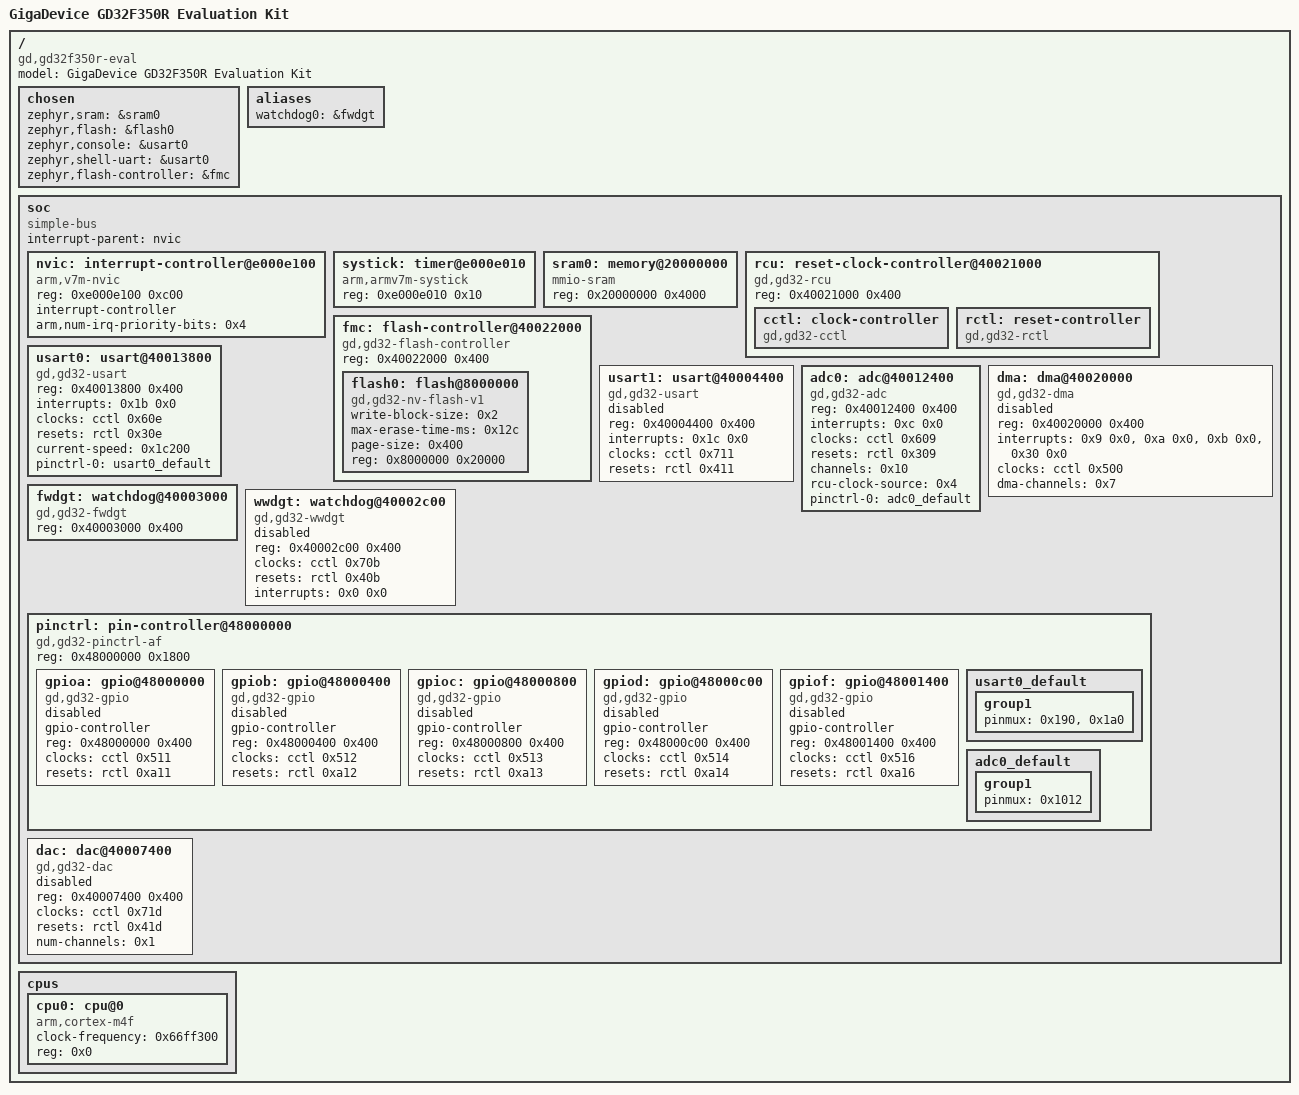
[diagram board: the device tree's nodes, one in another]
/dts-v1/;

/* node '/' defined in zephyr/dts/common/skeleton.dtsi:9 */
/ {
	#address-cells = < 0x1 >;                      /* in zephyr/dts/common/skeleton.dtsi:10 */
	#size-cells = < 0x1 >;                         /* in zephyr/dts/common/skeleton.dtsi:11 */
	model = "GigaDevice GD32F350R Evaluation Kit"; /* in zephyr/boards/gd/gd32f350r_eval/gd32f350r_eval.dts:12 */
	compatible = "gd,gd32f350r-eval";              /* in zephyr/boards/gd/gd32f350r_eval/gd32f350r_eval.dts:13 */

	/* node '/chosen' defined in zephyr/dts/common/skeleton.dtsi:13 */
	chosen {
		zephyr,sram = &sram0;           /* in zephyr/boards/gd/gd32f350r_eval/gd32f350r_eval.dts:16 */
		zephyr,flash = &flash0;         /* in zephyr/boards/gd/gd32f350r_eval/gd32f350r_eval.dts:17 */
		zephyr,console = &usart0;       /* in zephyr/boards/gd/gd32f350r_eval/gd32f350r_eval.dts:18 */
		zephyr,shell-uart = &usart0;    /* in zephyr/boards/gd/gd32f350r_eval/gd32f350r_eval.dts:19 */
		zephyr,flash-controller = &fmc; /* in zephyr/boards/gd/gd32f350r_eval/gd32f350r_eval.dts:20 */
	};

	/* node '/aliases' defined in zephyr/dts/common/skeleton.dtsi:15 */
	aliases {
		watchdog0 = &fwdgt; /* in zephyr/boards/gd/gd32f350r_eval/gd32f350r_eval.dts:24 */
	};

	/* node '/soc' defined in zephyr/dts/arm/armv7-m.dtsi:6 */
	soc {
		#address-cells = < 0x1 >;     /* in zephyr/dts/arm/armv7-m.dtsi:7 */
		#size-cells = < 0x1 >;        /* in zephyr/dts/arm/armv7-m.dtsi:8 */
		compatible = "simple-bus";    /* in zephyr/dts/arm/armv7-m.dtsi:9 */
		interrupt-parent = < &nvic >; /* in zephyr/dts/arm/armv7-m.dtsi:10 */
		ranges;                       /* in zephyr/dts/arm/armv7-m.dtsi:11 */

		/* node '/soc/interrupt-controller@e000e100' defined in zephyr/dts/arm/armv7-m.dtsi:13 */
		nvic: interrupt-controller@e000e100 {
			#address-cells = < 0x1 >;            /* in zephyr/dts/arm/armv7-m.dtsi:14 */
			compatible = "arm,v7m-nvic";         /* in zephyr/dts/arm/armv7-m.dtsi:15 */
			reg = < 0xe000e100 0xc00 >;          /* in zephyr/dts/arm/armv7-m.dtsi:16 */
			interrupt-controller;                /* in zephyr/dts/arm/armv7-m.dtsi:17 */
			#interrupt-cells = < 0x2 >;          /* in zephyr/dts/arm/armv7-m.dtsi:18 */
			arm,num-irq-priority-bits = < 0x4 >; /* in zephyr/dts/arm/gd/gd32f3x0/gd32f3x0.dtsi:181 */
			phandle = < 0x1 >;                   /* in zephyr/dts/arm/armv7-m.dtsi:10 */
		};

		/* node '/soc/timer@e000e010' defined in zephyr/dts/arm/armv7-m.dtsi:21 */
		systick: timer@e000e010 {
			compatible = "arm,armv7m-systick"; /* in zephyr/dts/arm/armv7-m.dtsi:22 */
			reg = < 0xe000e010 0x10 >;         /* in zephyr/dts/arm/armv7-m.dtsi:23 */
		};

		/* node '/soc/memory@20000000' defined in zephyr/dts/arm/gd/gd32f3x0/gd32f3x0.dtsi:28 */
		sram0: memory@20000000 {
			compatible = "mmio-sram";    /* in zephyr/dts/arm/gd/gd32f3x0/gd32f3x0.dtsi:29 */
			reg = < 0x20000000 0x4000 >; /* in zephyr/dts/arm/gd/gd32f3x0/gd32f350rb.dtsi:15 */
		};

		/* node '/soc/reset-clock-controller@40021000' defined in zephyr/dts/arm/gd/gd32f3x0/gd32f3x0.dtsi:32 */
		rcu: reset-clock-controller@40021000 {
			compatible = "gd,gd32-rcu"; /* in zephyr/dts/arm/gd/gd32f3x0/gd32f3x0.dtsi:33 */
			reg = < 0x40021000 0x400 >; /* in zephyr/dts/arm/gd/gd32f3x0/gd32f3x0.dtsi:34 */
			status = "okay";            /* in zephyr/dts/arm/gd/gd32f3x0/gd32f3x0.dtsi:35 */

			/* node '/soc/reset-clock-controller@40021000/clock-controller' defined in zephyr/dts/arm/gd/gd32f3x0/gd32f3x0.dtsi:37 */
			cctl: clock-controller {
				compatible = "gd,gd32-cctl"; /* in zephyr/dts/arm/gd/gd32f3x0/gd32f3x0.dtsi:38 */
				#clock-cells = < 0x1 >;      /* in zephyr/dts/arm/gd/gd32f3x0/gd32f3x0.dtsi:39 */
				status = "okay";             /* in zephyr/dts/arm/gd/gd32f3x0/gd32f3x0.dtsi:40 */
				phandle = < 0x2 >;           /* in zephyr/dts/arm/gd/gd32f3x0/gd32f3x0.dtsi:69 */
			};

			/* node '/soc/reset-clock-controller@40021000/reset-controller' defined in zephyr/dts/arm/gd/gd32f3x0/gd32f3x0.dtsi:43 */
			rctl: reset-controller {
				compatible = "gd,gd32-rctl"; /* in zephyr/dts/arm/gd/gd32f3x0/gd32f3x0.dtsi:44 */
				#reset-cells = < 0x1 >;      /* in zephyr/dts/arm/gd/gd32f3x0/gd32f3x0.dtsi:45 */
				status = "okay";             /* in zephyr/dts/arm/gd/gd32f3x0/gd32f3x0.dtsi:46 */
				phandle = < 0x3 >;           /* in zephyr/dts/arm/gd/gd32f3x0/gd32f3x0.dtsi:70 */
			};
		};

		/* node '/soc/flash-controller@40022000' defined in zephyr/dts/arm/gd/gd32f3x0/gd32f3x0.dtsi:50 */
		fmc: flash-controller@40022000 {
			compatible = "gd,gd32-flash-controller"; /* in zephyr/dts/arm/gd/gd32f3x0/gd32f3x0.dtsi:51 */
			reg = < 0x40022000 0x400 >;              /* in zephyr/dts/arm/gd/gd32f3x0/gd32f3x0.dtsi:52 */
			#address-cells = < 0x1 >;                /* in zephyr/dts/arm/gd/gd32f3x0/gd32f3x0.dtsi:54 */
			#size-cells = < 0x1 >;                   /* in zephyr/dts/arm/gd/gd32f3x0/gd32f3x0.dtsi:55 */

			/* node '/soc/flash-controller@40022000/flash@8000000' defined in zephyr/dts/arm/gd/gd32f3x0/gd32f3x0.dtsi:57 */
			flash0: flash@8000000 {
				compatible = "gd,gd32-nv-flash-v1",
				             "soc-nv-flash";        /* in zephyr/dts/arm/gd/gd32f3x0/gd32f3x0.dtsi:58 */
				write-block-size = < 0x2 >;         /* in zephyr/dts/arm/gd/gd32f3x0/gd32f3x0.dtsi:59 */
				max-erase-time-ms = < 0x12c >;      /* in zephyr/dts/arm/gd/gd32f3x0/gd32f3x0.dtsi:60 */
				page-size = < 0x400 >;              /* in zephyr/dts/arm/gd/gd32f3x0/gd32f3x0.dtsi:61 */
				reg = < 0x8000000 0x20000 >;        /* in zephyr/dts/arm/gd/gd32f3x0/gd32f350rb.dtsi:11 */
			};
		};

		/* node '/soc/usart@40013800' defined in zephyr/dts/arm/gd/gd32f3x0/gd32f3x0.dtsi:65 */
		usart0: usart@40013800 {
			compatible = "gd,gd32-usart";    /* in zephyr/dts/arm/gd/gd32f3x0/gd32f3x0.dtsi:66 */
			reg = < 0x40013800 0x400 >;      /* in zephyr/dts/arm/gd/gd32f3x0/gd32f3x0.dtsi:67 */
			interrupts = < 0x1b 0x0 >;       /* in zephyr/dts/arm/gd/gd32f3x0/gd32f3x0.dtsi:68 */
			clocks = < &cctl 0x60e >;        /* in zephyr/dts/arm/gd/gd32f3x0/gd32f3x0.dtsi:69 */
			resets = < &rctl 0x30e >;        /* in zephyr/dts/arm/gd/gd32f3x0/gd32f3x0.dtsi:70 */
			status = "okay";                 /* in zephyr/boards/gd/gd32f350r_eval/gd32f350r_eval.dts:29 */
			current-speed = < 0x1c200 >;     /* in zephyr/boards/gd/gd32f350r_eval/gd32f350r_eval.dts:30 */
			pinctrl-0 = < &usart0_default >; /* in zephyr/boards/gd/gd32f350r_eval/gd32f350r_eval.dts:31 */
			pinctrl-names = "default";       /* in zephyr/boards/gd/gd32f350r_eval/gd32f350r_eval.dts:32 */
		};

		/* node '/soc/usart@40004400' defined in zephyr/dts/arm/gd/gd32f3x0/gd32f3x0.dtsi:74 */
		usart1: usart@40004400 {
			compatible = "gd,gd32-usart"; /* in zephyr/dts/arm/gd/gd32f3x0/gd32f3x0.dtsi:75 */
			reg = < 0x40004400 0x400 >;   /* in zephyr/dts/arm/gd/gd32f3x0/gd32f3x0.dtsi:76 */
			interrupts = < 0x1c 0x0 >;    /* in zephyr/dts/arm/gd/gd32f3x0/gd32f3x0.dtsi:77 */
			clocks = < &cctl 0x711 >;     /* in zephyr/dts/arm/gd/gd32f3x0/gd32f3x0.dtsi:78 */
			resets = < &rctl 0x411 >;     /* in zephyr/dts/arm/gd/gd32f3x0/gd32f3x0.dtsi:79 */
			status = "disabled";          /* in zephyr/dts/arm/gd/gd32f3x0/gd32f3x0.dtsi:80 */
		};

		/* node '/soc/adc@40012400' defined in zephyr/dts/arm/gd/gd32f3x0/gd32f3x0.dtsi:83 */
		adc0: adc@40012400 {
			compatible = "gd,gd32-adc";    /* in zephyr/dts/arm/gd/gd32f3x0/gd32f3x0.dtsi:84 */
			reg = < 0x40012400 0x400 >;    /* in zephyr/dts/arm/gd/gd32f3x0/gd32f3x0.dtsi:85 */
			interrupts = < 0xc 0x0 >;      /* in zephyr/dts/arm/gd/gd32f3x0/gd32f3x0.dtsi:86 */
			clocks = < &cctl 0x609 >;      /* in zephyr/dts/arm/gd/gd32f3x0/gd32f3x0.dtsi:88 */
			resets = < &rctl 0x309 >;      /* in zephyr/dts/arm/gd/gd32f3x0/gd32f3x0.dtsi:89 */
			channels = < 0x10 >;           /* in zephyr/dts/arm/gd/gd32f3x0/gd32f3x0.dtsi:90 */
			#io-channel-cells = < 0x1 >;   /* in zephyr/dts/arm/gd/gd32f3x0/gd32f3x0.dtsi:92 */
			status = "okay";               /* in zephyr/boards/gd/gd32f350r_eval/gd32f350r_eval.dts:36 */
			rcu-clock-source = < 0x4 >;    /* in zephyr/boards/gd/gd32f350r_eval/gd32f350r_eval.dts:38 */
			pinctrl-0 = < &adc0_default >; /* in zephyr/boards/gd/gd32f350r_eval/gd32f350r_eval.dts:39 */
			pinctrl-names = "default";     /* in zephyr/boards/gd/gd32f350r_eval/gd32f350r_eval.dts:40 */
		};

		/* node '/soc/dma@40020000' defined in zephyr/dts/arm/gd/gd32f3x0/gd32f3x0.dtsi:95 */
		dma: dma@40020000 {
			compatible = "gd,gd32-dma"; /* in zephyr/dts/arm/gd/gd32f3x0/gd32f3x0.dtsi:96 */
			reg = < 0x40020000 0x400 >; /* in zephyr/dts/arm/gd/gd32f3x0/gd32f3x0.dtsi:97 */
			interrupts = < 0x9 0x0 >,
			             < 0xa 0x0 >,
			             < 0xb 0x0 >,
			             < 0x30 0x0 >;  /* in zephyr/dts/arm/gd/gd32f3x0/gd32f3x0.dtsi:98 */
			clocks = < &cctl 0x500 >;   /* in zephyr/dts/arm/gd/gd32f3x0/gd32f3x0.dtsi:99 */
			dma-channels = < 0x7 >;     /* in zephyr/dts/arm/gd/gd32f3x0/gd32f3x0.dtsi:100 */
			#dma-cells = < 0x2 >;       /* in zephyr/dts/arm/gd/gd32f3x0/gd32f3x0.dtsi:101 */
			status = "disabled";        /* in zephyr/dts/arm/gd/gd32f3x0/gd32f3x0.dtsi:102 */
		};

		/* node '/soc/watchdog@40003000' defined in zephyr/dts/arm/gd/gd32f3x0/gd32f3x0.dtsi:105 */
		fwdgt: watchdog@40003000 {
			compatible = "gd,gd32-fwdgt"; /* in zephyr/dts/arm/gd/gd32f3x0/gd32f3x0.dtsi:106 */
			reg = < 0x40003000 0x400 >;   /* in zephyr/dts/arm/gd/gd32f3x0/gd32f3x0.dtsi:107 */
			status = "okay";              /* in zephyr/boards/gd/gd32f350r_eval/gd32f350r_eval.dts:44 */
		};

		/* node '/soc/watchdog@40002c00' defined in zephyr/dts/arm/gd/gd32f3x0/gd32f3x0.dtsi:111 */
		wwdgt: watchdog@40002c00 {
			compatible = "gd,gd32-wwdgt"; /* in zephyr/dts/arm/gd/gd32f3x0/gd32f3x0.dtsi:112 */
			reg = < 0x40002c00 0x400 >;   /* in zephyr/dts/arm/gd/gd32f3x0/gd32f3x0.dtsi:113 */
			clocks = < &cctl 0x70b >;     /* in zephyr/dts/arm/gd/gd32f3x0/gd32f3x0.dtsi:114 */
			resets = < &rctl 0x40b >;     /* in zephyr/dts/arm/gd/gd32f3x0/gd32f3x0.dtsi:115 */
			interrupts = < 0x0 0x0 >;     /* in zephyr/dts/arm/gd/gd32f3x0/gd32f3x0.dtsi:116 */
			status = "disabled";          /* in zephyr/dts/arm/gd/gd32f3x0/gd32f3x0.dtsi:117 */
		};

		/* node '/soc/pin-controller@48000000' defined in zephyr/dts/arm/gd/gd32f3x0/gd32f3x0.dtsi:120 */
		pinctrl: pin-controller@48000000 {
			compatible = "gd,gd32-pinctrl-af"; /* in zephyr/dts/arm/gd/gd32f3x0/gd32f3x0.dtsi:121 */
			reg = < 0x48000000 0x1800 >;       /* in zephyr/dts/arm/gd/gd32f3x0/gd32f3x0.dtsi:122 */
			#address-cells = < 0x1 >;          /* in zephyr/dts/arm/gd/gd32f3x0/gd32f3x0.dtsi:123 */
			#size-cells = < 0x1 >;             /* in zephyr/dts/arm/gd/gd32f3x0/gd32f3x0.dtsi:124 */
			status = "okay";                   /* in zephyr/dts/arm/gd/gd32f3x0/gd32f3x0.dtsi:125 */

			/* node '/soc/pin-controller@48000000/gpio@48000000' defined in zephyr/dts/arm/gd/gd32f3x0/gd32f3x0.dtsi:127 */
			gpioa: gpio@48000000 {
				compatible = "gd,gd32-gpio"; /* in zephyr/dts/arm/gd/gd32f3x0/gd32f3x0.dtsi:128 */
				gpio-controller;             /* in zephyr/dts/arm/gd/gd32f3x0/gd32f3x0.dtsi:129 */
				#gpio-cells = < 0x2 >;       /* in zephyr/dts/arm/gd/gd32f3x0/gd32f3x0.dtsi:130 */
				reg = < 0x48000000 0x400 >;  /* in zephyr/dts/arm/gd/gd32f3x0/gd32f3x0.dtsi:131 */
				clocks = < &cctl 0x511 >;    /* in zephyr/dts/arm/gd/gd32f3x0/gd32f3x0.dtsi:132 */
				resets = < &rctl 0xa11 >;    /* in zephyr/dts/arm/gd/gd32f3x0/gd32f3x0.dtsi:133 */
				status = "disabled";         /* in zephyr/dts/arm/gd/gd32f3x0/gd32f3x0.dtsi:134 */
			};

			/* node '/soc/pin-controller@48000000/gpio@48000400' defined in zephyr/dts/arm/gd/gd32f3x0/gd32f3x0.dtsi:137 */
			gpiob: gpio@48000400 {
				compatible = "gd,gd32-gpio"; /* in zephyr/dts/arm/gd/gd32f3x0/gd32f3x0.dtsi:138 */
				gpio-controller;             /* in zephyr/dts/arm/gd/gd32f3x0/gd32f3x0.dtsi:139 */
				#gpio-cells = < 0x2 >;       /* in zephyr/dts/arm/gd/gd32f3x0/gd32f3x0.dtsi:140 */
				reg = < 0x48000400 0x400 >;  /* in zephyr/dts/arm/gd/gd32f3x0/gd32f3x0.dtsi:141 */
				clocks = < &cctl 0x512 >;    /* in zephyr/dts/arm/gd/gd32f3x0/gd32f3x0.dtsi:142 */
				resets = < &rctl 0xa12 >;    /* in zephyr/dts/arm/gd/gd32f3x0/gd32f3x0.dtsi:143 */
				status = "disabled";         /* in zephyr/dts/arm/gd/gd32f3x0/gd32f3x0.dtsi:144 */
			};

			/* node '/soc/pin-controller@48000000/gpio@48000800' defined in zephyr/dts/arm/gd/gd32f3x0/gd32f3x0.dtsi:147 */
			gpioc: gpio@48000800 {
				compatible = "gd,gd32-gpio"; /* in zephyr/dts/arm/gd/gd32f3x0/gd32f3x0.dtsi:148 */
				gpio-controller;             /* in zephyr/dts/arm/gd/gd32f3x0/gd32f3x0.dtsi:149 */
				#gpio-cells = < 0x2 >;       /* in zephyr/dts/arm/gd/gd32f3x0/gd32f3x0.dtsi:150 */
				reg = < 0x48000800 0x400 >;  /* in zephyr/dts/arm/gd/gd32f3x0/gd32f3x0.dtsi:151 */
				clocks = < &cctl 0x513 >;    /* in zephyr/dts/arm/gd/gd32f3x0/gd32f3x0.dtsi:152 */
				resets = < &rctl 0xa13 >;    /* in zephyr/dts/arm/gd/gd32f3x0/gd32f3x0.dtsi:153 */
				status = "disabled";         /* in zephyr/dts/arm/gd/gd32f3x0/gd32f3x0.dtsi:154 */
			};

			/* node '/soc/pin-controller@48000000/gpio@48000c00' defined in zephyr/dts/arm/gd/gd32f3x0/gd32f3x0.dtsi:157 */
			gpiod: gpio@48000c00 {
				compatible = "gd,gd32-gpio"; /* in zephyr/dts/arm/gd/gd32f3x0/gd32f3x0.dtsi:158 */
				gpio-controller;             /* in zephyr/dts/arm/gd/gd32f3x0/gd32f3x0.dtsi:159 */
				#gpio-cells = < 0x2 >;       /* in zephyr/dts/arm/gd/gd32f3x0/gd32f3x0.dtsi:160 */
				reg = < 0x48000c00 0x400 >;  /* in zephyr/dts/arm/gd/gd32f3x0/gd32f3x0.dtsi:161 */
				clocks = < &cctl 0x514 >;    /* in zephyr/dts/arm/gd/gd32f3x0/gd32f3x0.dtsi:162 */
				resets = < &rctl 0xa14 >;    /* in zephyr/dts/arm/gd/gd32f3x0/gd32f3x0.dtsi:163 */
				status = "disabled";         /* in zephyr/dts/arm/gd/gd32f3x0/gd32f3x0.dtsi:164 */
			};

			/* node '/soc/pin-controller@48000000/gpio@48001400' defined in zephyr/dts/arm/gd/gd32f3x0/gd32f3x0.dtsi:167 */
			gpiof: gpio@48001400 {
				compatible = "gd,gd32-gpio"; /* in zephyr/dts/arm/gd/gd32f3x0/gd32f3x0.dtsi:168 */
				gpio-controller;             /* in zephyr/dts/arm/gd/gd32f3x0/gd32f3x0.dtsi:169 */
				#gpio-cells = < 0x2 >;       /* in zephyr/dts/arm/gd/gd32f3x0/gd32f3x0.dtsi:170 */
				reg = < 0x48001400 0x400 >;  /* in zephyr/dts/arm/gd/gd32f3x0/gd32f3x0.dtsi:171 */
				clocks = < &cctl 0x516 >;    /* in zephyr/dts/arm/gd/gd32f3x0/gd32f3x0.dtsi:172 */
				resets = < &rctl 0xa16 >;    /* in zephyr/dts/arm/gd/gd32f3x0/gd32f3x0.dtsi:173 */
				status = "disabled";         /* in zephyr/dts/arm/gd/gd32f3x0/gd32f3x0.dtsi:174 */
			};

			/* node '/soc/pin-controller@48000000/usart0_default' defined in zephyr/boards/gd/gd32f350r_eval/gd32f350r_eval-pinctrl.dtsi:9 */
			usart0_default: usart0_default {
				phandle = < 0x4 >; /* in zephyr/boards/gd/gd32f350r_eval/gd32f350r_eval.dts:31 */

				/* node '/soc/pin-controller@48000000/usart0_default/group1' defined in zephyr/boards/gd/gd32f350r_eval/gd32f350r_eval-pinctrl.dtsi:10 */
				group1 {
					pinmux = < 0x190 >,
					         < 0x1a0 >; /* in zephyr/boards/gd/gd32f350r_eval/gd32f350r_eval-pinctrl.dtsi:11 */
				};
			};

			/* node '/soc/pin-controller@48000000/adc0_default' defined in zephyr/boards/gd/gd32f350r_eval/gd32f350r_eval-pinctrl.dtsi:15 */
			adc0_default: adc0_default {
				phandle = < 0x5 >; /* in zephyr/boards/gd/gd32f350r_eval/gd32f350r_eval.dts:39 */

				/* node '/soc/pin-controller@48000000/adc0_default/group1' defined in zephyr/boards/gd/gd32f350r_eval/gd32f350r_eval-pinctrl.dtsi:16 */
				group1 {
					pinmux = < 0x1012 >; /* in zephyr/boards/gd/gd32f350r_eval/gd32f350r_eval-pinctrl.dtsi:17 */
				};
			};
		};

		/* node '/soc/dac@40007400' defined in zephyr/dts/arm/gd/gd32f3x0/gd32f350.dtsi:12 */
		dac: dac@40007400 {
			compatible = "gd,gd32-dac";  /* in zephyr/dts/arm/gd/gd32f3x0/gd32f350.dtsi:13 */
			reg = < 0x40007400 0x400 >;  /* in zephyr/dts/arm/gd/gd32f3x0/gd32f350.dtsi:14 */
			clocks = < &cctl 0x71d >;    /* in zephyr/dts/arm/gd/gd32f3x0/gd32f350.dtsi:15 */
			resets = < &rctl 0x41d >;    /* in zephyr/dts/arm/gd/gd32f3x0/gd32f350.dtsi:16 */
			num-channels = < 0x1 >;      /* in zephyr/dts/arm/gd/gd32f3x0/gd32f350.dtsi:17 */
			status = "disabled";         /* in zephyr/dts/arm/gd/gd32f3x0/gd32f350.dtsi:18 */
			#io-channel-cells = < 0x1 >; /* in zephyr/dts/arm/gd/gd32f3x0/gd32f350.dtsi:19 */
		};
	};

	/* node '/cpus' defined in zephyr/dts/arm/gd/gd32f3x0/gd32f3x0.dtsi:16 */
	cpus {
		#address-cells = < 0x1 >; /* in zephyr/dts/arm/gd/gd32f3x0/gd32f3x0.dtsi:17 */
		#size-cells = < 0x0 >;    /* in zephyr/dts/arm/gd/gd32f3x0/gd32f3x0.dtsi:18 */

		/* node '/cpus/cpu@0' defined in zephyr/dts/arm/gd/gd32f3x0/gd32f3x0.dtsi:20 */
		cpu0: cpu@0 {
			clock-frequency = < 0x66ff300 >; /* in zephyr/dts/arm/gd/gd32f3x0/gd32f3x0.dtsi:21 */
			compatible = "arm,cortex-m4f";   /* in zephyr/dts/arm/gd/gd32f3x0/gd32f3x0.dtsi:22 */
			reg = < 0x0 >;                   /* in zephyr/dts/arm/gd/gd32f3x0/gd32f3x0.dtsi:23 */
		};
	};
};
